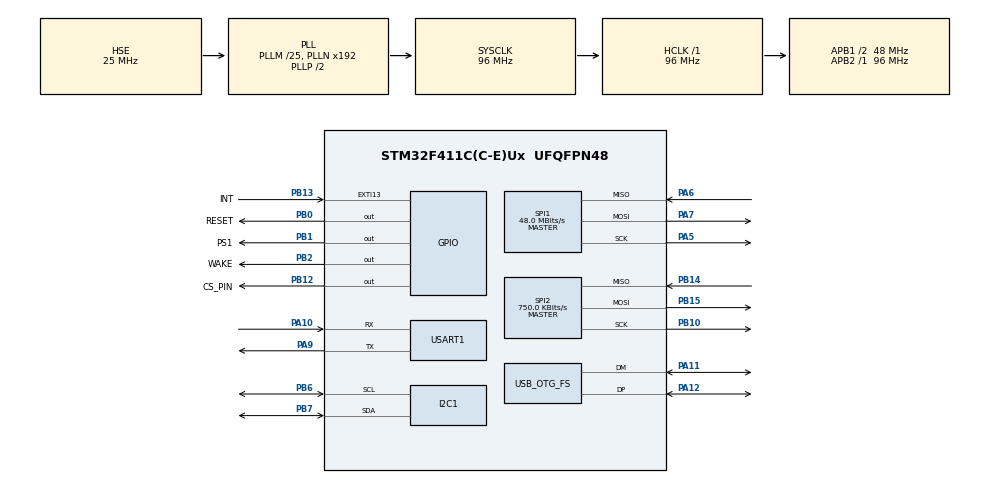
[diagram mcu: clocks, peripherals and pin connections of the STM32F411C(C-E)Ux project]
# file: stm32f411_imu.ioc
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Dma.I2C1_RX.0.Direction=DMA_PERIPH_TO_MEMORY
Dma.I2C1_RX.0.FIFOMode=DMA_FIFOMODE_DISABLE
Dma.I2C1_RX.0.Instance=DMA1_Stream0
Dma.I2C1_RX.0.MemDataAlignment=DMA_MDATAALIGN_BYTE
Dma.I2C1_RX.0.MemInc=DMA_MINC_ENABLE
Dma.I2C1_RX.0.Mode=DMA_NORMAL
Dma.I2C1_RX.0.PeriphDataAlignment=DMA_PDATAALIGN_BYTE
Dma.I2C1_RX.0.PeriphInc=DMA_PINC_DISABLE
Dma.I2C1_RX.0.Priority=DMA_PRIORITY_LOW
Dma.I2C1_TX.1.Direction=DMA_MEMORY_TO_PERIPH
Dma.I2C1_TX.1.FIFOMode=DMA_FIFOMODE_DISABLE
Dma.I2C1_TX.1.Instance=DMA1_Stream1
Dma.I2C1_TX.1.MemDataAlignment=DMA_MDATAALIGN_BYTE
Dma.I2C1_TX.1.MemInc=DMA_MINC_ENABLE
Dma.I2C1_TX.1.Mode=DMA_NORMAL
Dma.I2C1_TX.1.PeriphDataAlignment=DMA_PDATAALIGN_BYTE
Dma.I2C1_TX.1.PeriphInc=DMA_PINC_DISABLE
Dma.I2C1_TX.1.Priority=DMA_PRIORITY_LOW
Dma.Request0=I2C1_RX
Dma.Request1=I2C1_TX
Dma.Request2=SPI1_RX
Dma.Request3=SPI1_TX
Dma.SPI1_RX.2.Direction=DMA_PERIPH_TO_MEMORY
Dma.SPI1_RX.2.FIFOMode=DMA_FIFOMODE_DISABLE
Dma.SPI1_RX.2.Instance=DMA2_Stream0
Dma.SPI1_RX.2.MemDataAlignment=DMA_MDATAALIGN_BYTE
Dma.SPI1_RX.2.MemInc=DMA_MINC_ENABLE
Dma.SPI1_RX.2.Mode=DMA_NORMAL
Dma.SPI1_RX.2.PeriphDataAlignment=DMA_PDATAALIGN_BYTE
Dma.SPI1_RX.2.PeriphInc=DMA_PINC_DISABLE
Dma.SPI1_RX.2.Priority=DMA_PRIORITY_LOW
Dma.SPI1_TX.3.Direction=DMA_MEMORY_TO_PERIPH
Dma.SPI1_TX.3.FIFOMode=DMA_FIFOMODE_DISABLE
Dma.SPI1_TX.3.Instance=DMA2_Stream2
Dma.SPI1_TX.3.MemDataAlignment=DMA_MDATAALIGN_BYTE
Dma.SPI1_TX.3.MemInc=DMA_MINC_ENABLE
Dma.SPI1_TX.3.Mode=DMA_NORMAL
Dma.SPI1_TX.3.PeriphDataAlignment=DMA_PDATAALIGN_BYTE
Dma.SPI1_TX.3.PeriphInc=DMA_PINC_DISABLE
Dma.SPI1_TX.3.Priority=DMA_PRIORITY_LOW
FREERTOS.Tasks01=defaultTask,24,128,StartDefaultTask,Default,NULL,Dynamic,NULL,NULL
FREERTOS.configENABLE_FPU=1
FREERTOS.configUSE_IDLE_HOOK=1
FREERTOS.configUSE_TICK_HOOK=1
Mcu.Family=STM32F4
Mcu.Name=STM32F411C(C-E)Ux
Mcu.Package=UFQFPN48
NVIC.DMA1_Stream0_IRQn=true\:5\:0\:false\:false\:true\:true\:false\:true\:true
NVIC.DMA1_Stream1_IRQn=true\:5\:0\:false\:false\:true\:true\:false\:true\:true
NVIC.DMA2_Stream0_IRQn=true\:5\:0\:false\:false\:true\:true\:false\:true\:true
NVIC.DMA2_Stream2_IRQn=true\:5\:0\:false\:false\:true\:true\:false\:true\:true
NVIC.I2C1_ER_IRQn=true\:5\:0\:false\:false\:true\:true\:true\:true\:true
NVIC.I2C1_EV_IRQn=true\:5\:0\:false\:false\:true\:true\:true\:true\:true
NVIC.OTG_FS_IRQn=true\:5\:0\:false\:false\:true\:true\:false\:true\:true
NVIC.PriorityGroup=NVIC_PRIORITYGROUP_4
NVIC.SPI1_IRQn=true\:5\:0\:false\:false\:true\:true\:true\:true\:true
NVIC.TIM1_TRG_COM_TIM11_IRQn=true\:15\:0\:false\:false\:true\:false\:false\:true\:true
NVIC.TimeBase=TIM1_TRG_COM_TIM11_IRQn
NVIC.TimeBaseIP=TIM11
PA10.Mode=Asynchronous
PA10.Signal=USART1_RX
PA11.Mode=Device_Only
PA11.Signal=USB_OTG_FS_DM
PA12.Mode=Device_Only
PA12.Signal=USB_OTG_FS_DP
PA13.Mode=Serial_Wire
PA13.Signal=SYS_JTMS-SWDIO
PA14.Mode=Serial_Wire
PA14.Signal=SYS_JTCK-SWCLK
PA5.GPIO_Speed=GPIO_SPEED_FREQ_VERY_HIGH
PA5.Mode=Full_Duplex_Master
PA5.Signal=SPI1_SCK
PA6.Mode=Full_Duplex_Master
PA6.Signal=SPI1_MISO
PA7.Mode=Full_Duplex_Master
PA7.Signal=SPI1_MOSI
PA9.Mode=Asynchronous
PA9.Signal=USART1_TX
PB0.GPIO_Label=RESET
PB0.PinState=GPIO_PIN_SET
PB0.Signal=GPIO_Output
PB1.GPIO_Label=PS1
PB1.PinState=GPIO_PIN_SET
PB1.Signal=GPIO_Output
PB10.Mode=Full_Duplex_Master
PB10.Signal=SPI2_SCK
PB12.GPIO_Label=CS_PIN
PB12.PinState=GPIO_PIN_SET
PB12.Signal=GPIO_Output
PB13.GPIO_Label=INT
PB13.GPIO_ModeDefaultEXTI=GPIO_MODE_IT_FALLING
PB13.GPIO_PuPd=GPIO_PULLUP
PB13.Signal=GPXTI13
PB14.Mode=Full_Duplex_Master
PB14.Signal=SPI2_MISO
PB15.Mode=Full_Duplex_Master
PB15.Signal=SPI2_MOSI
PB2.GPIO_Label=WAKE
PB2.PinState=GPIO_PIN_SET
PB2.Signal=GPIO_Output
PB6.Mode=I2C
PB6.Signal=I2C1_SCL
PB7.Mode=I2C
PB7.Signal=I2C1_SDA
PC14-OSC32_IN.Mode=LSE-External-Oscillator
PC14-OSC32_IN.Signal=RCC_OSC32_IN
PC15-OSC32_OUT.Mode=LSE-External-Oscillator
PC15-OSC32_OUT.Signal=RCC_OSC32_OUT
PH0\ -\ OSC_IN.Mode=HSE-External-Oscillator
PH0\ -\ OSC_IN.Signal=RCC_OSC_IN
PH1\ -\ OSC_OUT.Mode=HSE-External-Oscillator
PH1\ -\ OSC_OUT.Signal=RCC_OSC_OUT
ProjectManager.HeapSize=0x200
ProjectManager.StackSize=0x400
ProjectManager.TargetToolchain=STM32CubeIDE
RCC.48MHZClocksFreq_Value=48000000
RCC.AHBFreq_Value=96000000
RCC.APB1CLKDivider=RCC_HCLK_DIV2
RCC.APB1Freq_Value=48000000
RCC.APB1TimFreq_Value=96000000
RCC.APB2Freq_Value=96000000
RCC.APB2TimFreq_Value=96000000
RCC.CortexFreq_Value=96000000
RCC.HCLKFreq_Value=96000000
RCC.HSE_VALUE=25000000
RCC.HSI_VALUE=16000000
RCC.PLLM=25
RCC.SYSCLKFreq_VALUE=96000000
RCC.SYSCLKSource=RCC_SYSCLKSOURCE_PLLCLK
RCC.VCOOutputFreq_Value=192000000
SPI1.BaudRatePrescaler=SPI_BAUDRATEPRESCALER_2
SPI1.CalculateBaudRate=48.0 MBits/s
SPI1.Direction=SPI_DIRECTION_2LINES
SPI1.Mode=SPI_MODE_MASTER
SPI1.VirtualType=VM_MASTER
SPI2.BaudRatePrescaler=SPI_BAUDRATEPRESCALER_64
SPI2.CLKPhase=SPI_PHASE_2EDGE
SPI2.CLKPolarity=SPI_POLARITY_HIGH
SPI2.CalculateBaudRate=750.0 KBits/s
SPI2.Direction=SPI_DIRECTION_2LINES
SPI2.Mode=SPI_MODE_MASTER
SPI2.VirtualType=VM_MASTER
USART1.VirtualMode=VM_ASYNC
USB_DEVICE.CLASS_NAME_FS=CDC
USB_DEVICE.VirtualMode=Cdc
USB_DEVICE.VirtualModeFS=Cdc_FS
USB_OTG_FS.VirtualMode=Device_Only
VP_FREERTOS_VS_CMSIS_V2.Mode=CMSIS_V2
VP_SYS_VS_tim11.Mode=TIM11
VP_USB_DEVICE_VS_USB_DEVICE_CDC_FS.Mode=CDC_FS
board=custom

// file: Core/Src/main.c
/* USER CODE BEGIN Header */
/**
  ******************************************************************************
  * @file           : main.c
  * @brief          : Main program body
  ******************************************************************************
  * @attention
  *
  * Copyright (c) 2026 STMicroelectronics.
  * All rights reserved.
  *
  * This software is licensed under terms that can be found in the LICENSE file
  * in the root directory of this software component.
  * If no LICENSE file comes with this software, it is provided AS-IS.
  *
  ******************************************************************************
  */
/* USER CODE END Header */
#include "main.h"
#include "cmsis_os.h"
#include "dma.h"
#include "i2c.h"
#include "spi.h"
#include "usart.h"
#include "usb_device.h"
#include "gpio.h"

/* USER CODE BEGIN Includes */
#include "bn008x.h"
/* USER CODE END Includes */

void SystemClock_Config(void);
void MX_FREERTOS_Init(void);

int main(void)
{

  /* USER CODE BEGIN 1 */
	bn008x_hal_t hal;
	bn008x_status_t var;
	bn008x_t bn;
  /* USER CODE END 1 */

  /* MCU Configuration--------------------------------------------------------*/

  /* Reset of all peripherals, Initializes the Flash interface and the Systick. */
  HAL_Init();

  /* Configure the system clock */
  SystemClock_Config();

  /* Initialize all configured peripherals */
  MX_GPIO_Init();
  MX_DMA_Init();
  MX_I2C1_Init();
  MX_SPI1_Init();
  MX_USART1_UART_Init();
  MX_SPI2_Init();
  /* USER CODE BEGIN 2 */
  HAL_Delay(10);
  bn008x_hal_init(&hal);
  var = bn008x_init(&bn, &hal, &hspi2, 1, 3, 4, 0, 2);
  /* USER CODE END 2 */

  /* Init scheduler */
  //osKernelInitialize();  /* Call init function for freertos objects (in cmsis_os2.c) */
  //MX_FREERTOS_Init();

  /* Start scheduler */
  //osKernelStart();

  /* We should never get here as control is now taken by the scheduler */

  /* Infinite loop */
  while (1)
  {

  }
}

void SystemClock_Config(void)
{
  RCC_OscInitTypeDef RCC_OscInitStruct = {0};
  RCC_ClkInitTypeDef RCC_ClkInitStruct = {0};

  /** Configure the main internal regulator output voltage
  */
  __HAL_RCC_PWR_CLK_ENABLE();
  __HAL_PWR_VOLTAGESCALING_CONFIG(PWR_REGULATOR_VOLTAGE_SCALE1);

  /** Initializes the RCC Oscillators according to the specified parameters
  * in the RCC_OscInitTypeDef structure.
  */
  RCC_OscInitStruct.OscillatorType = RCC_OSCILLATORTYPE_HSE;
  RCC_OscInitStruct.HSEState = RCC_HSE_ON;
  RCC_OscInitStruct.PLL.PLLState = RCC_PLL_ON;
  RCC_OscInitStruct.PLL.PLLSource = RCC_PLLSOURCE_HSE;
  RCC_OscInitStruct.PLL.PLLM = 25;
  RCC_OscInitStruct.PLL.PLLN = 192;
  RCC_OscInitStruct.PLL.PLLP = RCC_PLLP_DIV2;
  RCC_OscInitStruct.PLL.PLLQ = 4;
  if (HAL_RCC_OscConfig(&RCC_OscInitStruct) != HAL_OK)
  {
    Error_Handler();
  }

  /** Initializes the CPU, AHB and APB buses clocks
  */
  RCC_ClkInitStruct.ClockType = RCC_CLOCKTYPE_HCLK|RCC_CLOCKTYPE_SYSCLK
                              |RCC_CLOCKTYPE_PCLK1|RCC_CLOCKTYPE_PCLK2;
  RCC_ClkInitStruct.SYSCLKSource = RCC_SYSCLKSOURCE_PLLCLK;
  RCC_ClkInitStruct.AHBCLKDivider = RCC_SYSCLK_DIV1;
  RCC_ClkInitStruct.APB1CLKDivider = RCC_HCLK_DIV2;
  RCC_ClkInitStruct.APB2CLKDivider = RCC_HCLK_DIV1;

  if (HAL_RCC_ClockConfig(&RCC_ClkInitStruct, FLASH_LATENCY_3) != HAL_OK)
  {
    Error_Handler();
  }
}

void HAL_TIM_PeriodElapsedCallback(TIM_HandleTypeDef *htim)
{
  if (htim->Instance == TIM11)
  {
    HAL_IncTick();
  }
}

void Error_Handler(void)
{
  __disable_irq();
  while (1)
  {
  }
}
